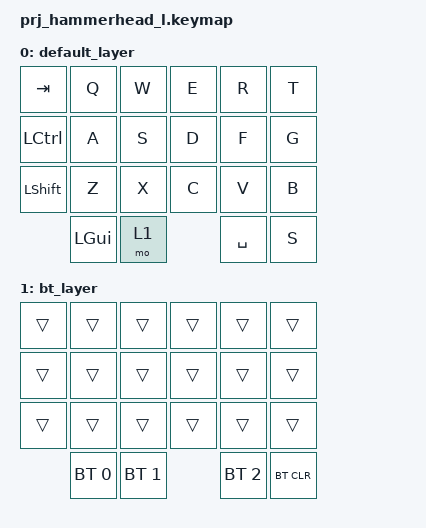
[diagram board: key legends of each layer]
#include <behaviors.dtsi>
#include <dt-bindings/zmk/keys.h>
#include <dt-bindings/zmk/bt.h>

/ {
        keymap {
                compatible = "zmk,keymap";

                default_layer {
// --------------------------------------
// |  TAB |  Q  |  W  |  E  |  R  |  T  |
// | CTRL |  A  |  S  |  D  |  F  |  G  |
// | SHFT |  Z  |  X  |  C  |  V  |  B  |
//                    | GUI | LWR | SPC |
                        bindings = <
   &kp TAB   &kp Q &kp W &kp E &kp R &kp T
   &kp LCTRL &kp A &kp S &kp D &kp F &kp G
   &kp LSHFT &kp Z &kp X &kp C &kp V &kp B
             &kp LGUI &mo 1 &kp SPACE&kp S
                        >;
                };


                bt_layer {
// --------------------------------------
// |      |     |     |     |     |     |
// |      |     |     |     |     |     |
// |      |     |     |     |     |     |
//              | bt0 | bt1 | bt1 |btclr|   
                        bindings = <
   &trans &trans &trans &trans &trans &trans
   &trans &trans &trans &trans &trans &trans
   &trans &trans &trans &trans &trans &trans
               &bt BT_SEL 0 &bt BT_SEL 1 &bt BT_SEL 2 &bt BT_CLR
                        >;
                };
        };
};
